# MINI58DE_v1 register map
File version: 1.0
Registers are 32-bit, read-write, reset 0x0 unless marked. A register's access mark holds for its fields unless they carry their own. Offsets are from the block's base; [hi:lo] are bit positions; 'fields as' and 'values as' point back to an identical list.

## ACMP — ACMP Register Map
Base 0x400D0000
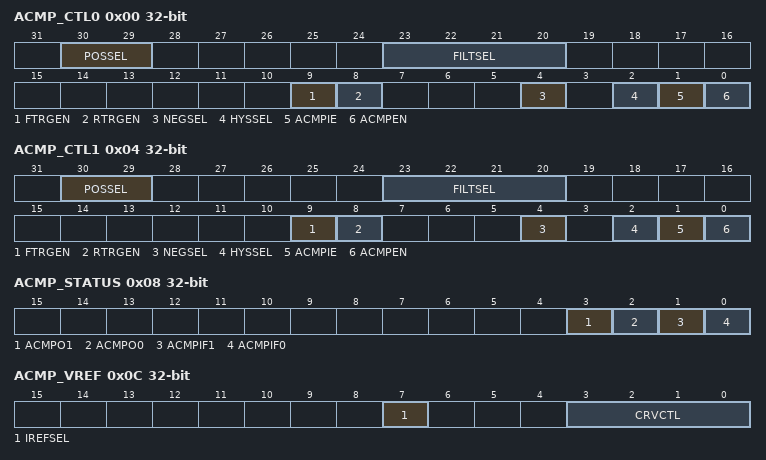
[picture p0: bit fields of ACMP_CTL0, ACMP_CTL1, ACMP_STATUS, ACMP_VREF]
0x00 ACMP_CTL0 — Analog Comparator 0 Control Register
  [30:29] POSSEL — Analog Comparator 0 Positive Input Selection
    0=ACMP0_Px is from ACMP0_P0 (P1.5) pin; 1=ACMP0_Px is from ACMP0_P1 (P1.0) pin; 2=ACMP0_Px is from ACMP0_P2 (P1.2) pin; 3=ACMP0_Px is from ACMP0_P3 (P1.3) pin
  [23:20] FILTSEL — Comparator Output Filter Count Selection
    0=Filter function is Disabled; 1=ACMP0 output is sampled 1 consecutive PCLK; 2=ACMP0 output is sampled 2 consecutive PCLKs; 3=ACMP0 output is sampled 4 consecutive PCLKs; 4=ACMP0 output is sampled 8 consecutive PCLKs; 5=ACMP0 output is sampled 16 consecutive PCLKs; 6=ACMP0 output is sampled 32 consecutive PCLKs; 7=ACMP0 output is sampled 64 consecutive PCLKs; 8=ACMP0 output is sampled 128 consecutive PCLKs; 9=ACMP0 output is sampled 256 consecutive PCLKs; 10=ACMP0 output is sampled 512 consecutive PCLKs
  [9] FTRGEN — Analog Comparator 0 Falling Edge Trigger Enable. Note: The bit is only effective while analog comparator 0 triggers PWM or Timer.
    0=Analog comparator 0 falling edge trigger PWM or Timer enabled; 1=Analog comparator 0 falling edge trigger disabled
  [8] RTRGEN — Analog Comparator 0 Rising Edge Trigger Enable Bit. Note: The bit is only effective while analog comparator 0 triggers PWM or Timer.
    0=Analog comparator 0 rising edge trigger PWM or Timer enabled; 1=Analog comparator 0 rising edge trigger disabled
  [4] NEGSEL — Analog Comparator 0 Negative Input Select Bit
    0=The source of the negative comparator input is from CPN0 pin; 1=The source of the negative comparator input is from internal band-gap voltage or comparator reference voltage
  [2] HYSSEL — Analog Comparator 0 Hysteresis Select Bit
    0=Hysteresis function Disabled; 1=Hysteresis function Enabled
  [1] ACMPIE — Analog Comparator 0 Interrupt Enable Bit
    0=Interrupt function Disabled; 1=Interrupt function Enabled
  [0] ACMPEN — Analog Comparator 0 Enable Bit. Note: Analog comparator output needs to wait 2 us stable time after this bit is set.
    0=Analog Comparator 0 Disabled; 1=Analog Comparator 1 Enabled
0x04 ACMP_CTL1 — Analog Comparator 1 Control Register
  [30:29] POSSEL — Analog Comparator 1 Positive Input Selection
    0=ACMP1_Px is from ACMP1_P0 (P3.1) pin; 1=ACMP1_Px is from ACMP1_P1 (P3.2) pin; 2=ACMP1_Px is from ACMP1_P2 (P3.4) pin; 3=ACMP1_Px is from ACMP1_P3 (P3.5) pin
  [23:20] FILTSEL — Comparator Output Filter Count Selection
    0=Filter function is Disabled; 1=ACMP1 output is sampled 1 consecutive PCLK; 2=ACMP1 output is sampled 2 consecutive PCLKs; 3=ACMP1 output is sampled 4 consecutive PCLKs; 4=ACMP1 output is sampled 8 consecutive PCLKs; 5=ACMP1 output is sampled 16 consecutive PCLKs; 6=ACMP1 output is sampled 32 consecutive PCLKs; 7=ACMP1 output is sampled 64 consecutive PCLKs; 8=ACMP1 output is sampled 128 consecutive PCLKs; 9=ACMP1 output is sampled 256 consecutive PCLKs; 10=ACMP1 output is sampled 512 consecutive PCLKs
  [9] FTRGEN — Analog Comparator 1 Falling Edge Trigger Enable Bit. Note: The bit is only effective while analog comparator 1 triggers PWM or Timer.
    0=Analog comparator 1 falling edge trigger PWM or Timer Enabled; 1=Analog comparator 1 falling edge trigger Disabled
  [8] RTRGEN — Analog Comparator 1 Rising Edge Trigger Enable Bit. Note: The bit is only effective while analog comparator 1 triggers PWM or Timer.
    0=Analog comparator 1 rising edge trigger PWM or Timer Enabled; 1=Analog comparator 1 rising edge trigger Disabled
  [4] NEGSEL — Analog Comparator 1 Negative Input Select Bit
    0=The source of the negative comparator input is from CPN1 pin; 1=The source of the negative comparator input is from internal band-gap voltage or comparator reference voltage
  [2] HYSSEL — Analog Comparator 1 Hysteresis Select Bit
    values as ACMP_CTL0.HYSSEL
  [1] ACMPIE — Analog Comparator 1 Interrupt Enable Bit
    0=Interrupt function Disabled; 1=Interrupt function Enabled
  [0] ACMPEN — Analog Comparator 1 Enable Bit. Note: Analog comparator output needs to wait 2 us stable time after this bit is set.
    0=Analog Comparator 1 Disabled; 1=Analog Comparator 1 Enabled
0x08 ACMP_STATUS — Analog Comparator 0/1 Status Register
  [3] ACMPO1 — Analog Comparator 1 Output
    0=Analog comparator 1 outputs 0; 1=Analog comparator 1 outputs 1
  [2] ACMPO0 — Analog Comparator 0 Output
    0=Analog comparator 0 outputs 0; 1=Analog comparator 0 outputs 1
  [1] ACMPIF1 — Analog Comparator 1 Flag. Note: This bit can be cleared to 0 by software writing 1.
    0=Analog comparator 1 output does not change; 1=Analog comparator 1 output changed
  [0] ACMPIF0 — Analog Comparator 0 Flag. Note: This bit can be cleared to 0 by software writing 1.
    0=Analog comparator 0 output does not change; 1=Analog comparator 0 output changed
0x0C ACMP_VREF — Analog Comparator Reference Voltage Control Register
  [7] IREFSEL — CRV Internal Reference Selection
    0=Band-gap voltage; 1=Internal comparator reference voltage
  [3:0] CRVCTL — Comparator Reference Voltage Control
